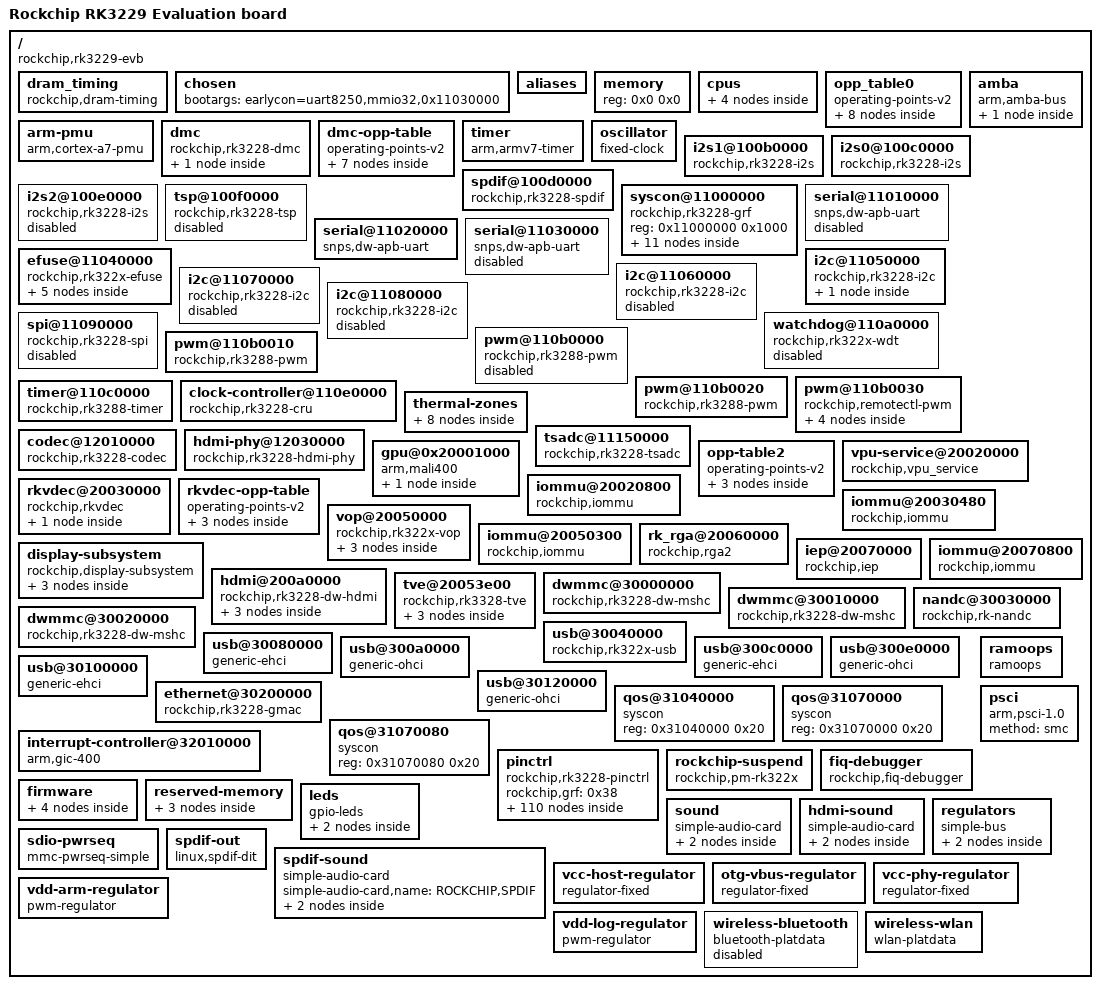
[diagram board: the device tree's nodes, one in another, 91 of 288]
/dts-v1/;

/ {
	#address-cells = <0x1>;
	#size-cells = <0x1>;
	interrupt-parent = <0x1>;
	model = "Rockchip RK3229 Evaluation board";
	compatible = "rockchip,rk3229-evb", "rockchip,rk3229";

	dram_timing {
		compatible = "rockchip,dram-timing";
		dram_spd_bin = <0x15>;
		sr_idle = <0x18>;
		pd_idle = <0x20>;
		dram_dll_disb_freq = <0x12c>;
		phy_dll_disb_freq = <0x190>;
		dram_odt_disb_freq = <0x190>;
		phy_odt_disb_freq = <0x190>;
		ddr3_drv = <0x0>;
		ddr3_odt = <0x40>;
		lpddr3_drv = <0x1>;
		lpddr3_odt = <0x3>;
		lpddr2_drv = <0x1>;
		phy_ddr3_clk_drv = <0x11>;
		phy_ddr3_cmd_drv = <0x11>;
		phy_ddr3_dqs_drv = <0x12>;
		phy_ddr3_odt = <0x2>;
		phy_lp23_clk_drv = <0x13>;
		phy_lp23_cmd_drv = <0x16>;
		phy_lp23_dqs_drv = <0x16>;
		phy_lp3_odt = <0x2>;
		phandle = <0xb>;
	};

	chosen {
		bootargs = "earlycon=uart8250,mmio32,0x11030000";
	};

	aliases {
		serial0 = "/serial@11010000";
		serial1 = "/serial@11020000";
		serial2 = "/serial@11030000";
		spi0 = "/spi@11090000";
	};

	memory {
		device_type = "memory";
		reg = <0x0 0x0>;
	};

	cpus {
		#address-cells = <0x1>;
		#size-cells = <0x0>;

		cpu@f00 {
			device_type = "cpu";
			compatible = "arm,cortex-a7";
			reg = <0xf00>;
			resets = <0x2 0x4>;
			operating-points-v2 = <0x3>;
			#cooling-cells = <0x2>;
			dynamic-power-coefficient = <0x7a>;
			clock-latency = <0x9c40>;
			clocks = <0x2 0x5>;
			enable-method = "psci";
			cpu-supply = <0x4>;
			phandle = <0x6>;
		};

		cpu@f01 {
			device_type = "cpu";
			compatible = "arm,cortex-a7";
			reg = <0xf01>;
			resets = <0x2 0x5>;
			operating-points-v2 = <0x3>;
			enable-method = "psci";
			phandle = <0x7>;
		};

		cpu@f02 {
			device_type = "cpu";
			compatible = "arm,cortex-a7";
			reg = <0xf02>;
			resets = <0x2 0x6>;
			operating-points-v2 = <0x3>;
			enable-method = "psci";
			phandle = <0x8>;
		};

		cpu@f03 {
			device_type = "cpu";
			compatible = "arm,cortex-a7";
			reg = <0xf03>;
			resets = <0x2 0x7>;
			operating-points-v2 = <0x3>;
			enable-method = "psci";
			phandle = <0x9>;
		};
	};

	opp_table0 {
		compatible = "operating-points-v2";
		opp-shared;
		clocks = <0x2 0x1>;
		rockchip,max-volt = <0x149970>;
		rockchip,leakage-voltage-sel = <0x1 0x4 0x0 0x5 0xfe 0x1>;
		nvmem-cells = <0x5>;
		nvmem-cell-names = "cpu_leakage";
		phandle = <0x3>;

		opp-408000000 {
			opp-hz = <0x0 0x18519600>;
			opp-microvolt = <0x12b128>;
			opp-microvolt-L0 = <0x12b128>;
			opp-microvolt-L1 = <0x12b128>;
			clock-latency-ns = <0x9c40>;
			opp-suspend;
		};

		opp-600000000 {
			opp-hz = <0x0 0x23c34600>;
			opp-microvolt = <0x1312d0>;
			opp-microvolt-L0 = <0x1312d0>;
			opp-microvolt-L1 = <0x1312d0>;
		};

		opp-816000000 {
			opp-hz = <0x0 0x30a32c00>;
			opp-microvolt = <0x137478>;
			opp-microvolt-L0 = <0x137478>;
			opp-microvolt-L1 = <0x137478>;
		};

		opp-1008000000 {
			opp-hz = <0x0 0x3c14dc00>;
			opp-microvolt = <0x13d620>;
			opp-microvolt-L0 = <0x13d620>;
			opp-microvolt-L1 = <0x13d620>;
		};

		opp-1200000000 {
			opp-hz = <0x0 0x47868c00>;
			opp-microvolt = <0x1437c8>;
			opp-microvolt-L0 = <0x1437c8>;
			opp-microvolt-L1 = <0x1437c8>;
		};

		opp-1296000000 {
			opp-hz = <0x0 0x4d3f6400>;
			opp-microvolt = <0x1437c8>;
			opp-microvolt-L0 = <0x1437c8>;
			opp-microvolt-L1 = <0x1437c8>;
		};

		opp-1392000000 {
			opp-hz = <0x0 0x52f83c00>;
			opp-microvolt = <0x149970>;
			opp-microvolt-L0 = <0x149970>;
			opp-microvolt-L1 = <0x149970>;
		};

		opp-1464000000 {
			opp-hz = <0x0 0x5742de00>;
			opp-microvolt = <0x149970>;
			opp-microvolt-L0 = <0x149970>;
			opp-microvolt-L1 = <0x149970>;
		};
	};

	amba {
		compatible = "arm,amba-bus";
		#address-cells = <0x1>;
		#size-cells = <0x1>;
		ranges;

		pdma@110f0000 {
			compatible = "arm,pl330", "arm,primecell";
			reg = <0x110f0000 0x4000>;
			interrupts = <0x0 0x0 0x4 0x0 0x1 0x4>;
			#dma-cells = <0x1>;
			clocks = <0x2 0xc2>;
			clock-names = "apb_pclk";
			peripherals-req-type-burst;
			phandle = <0xe>;
		};
	};

	arm-pmu {
		compatible = "arm,cortex-a7-pmu";
		interrupts = <0x0 0x4c 0x4 0x0 0x4d 0x4 0x0 0x4e 0x4 0x0 0x4f 0x4>;
		interrupt-affinity = <0x6 0x7 0x8 0x9>;
	};

	dmc {
		compatible = "rockchip,rk3228-dmc", "rockchip,rk322x-dram";
		clocks = <0x2 0x90>;
		clock-names = "dmc_clk";
		operating-points-v2 = <0xa>;
		system-status-freq = <0x1 0xc3500 0x10 0xc3500 0x10000 0xc3500>;
		dram_freq = <0x2faf0800>;
		rockchip,dram_timing = <0xb>;
		#cooling-cells = <0x2>;
		status = "okay";
		center-supply = <0xc>;

		ddr_power_model {
			compatible = "ddr_power_model";
			dynamic-power-coefficient = <0x78>;
			static-power-coefficient = <0xc8>;
			ts = <0x7d00 0x125c 0xffffffb0 0x2>;
			thermal-zone = "soc-thermal";
		};
	};

	dmc-opp-table {
		compatible = "operating-points-v2";
		rockchip,leakage-voltage-sel = <0x1 0x5 0x0 0x6 0xfe 0x1>;
		nvmem-cells = <0xd>;
		nvmem-cell-names = "ddr_leakage";
		phandle = <0xa>;

		opp-300000000 {
			opp-hz = <0x0 0x11e1a300>;
			opp-microvolt = <0x100590>;
			opp-microvolt-L0 = <0x100590>;
			opp-microvolt-L1 = <0xf4240>;
		};

		opp-400000000 {
			opp-hz = <0x0 0x17d78400>;
			opp-microvolt = <0x100590>;
			opp-microvolt-L0 = <0x100590>;
			opp-microvolt-L1 = <0xf4240>;
		};

		opp-600000000 {
			opp-hz = <0x0 0x23c34600>;
			opp-microvolt = <0x10c8e0>;
			opp-microvolt-L0 = <0x10c8e0>;
			opp-microvolt-L1 = <0x100590>;
		};

		opp-666000000 {
			opp-hz = <0x0 0x27b25a80>;
			opp-microvolt = <0x118c30>;
			opp-microvolt-L0 = <0x118c30>;
			opp-microvolt-L1 = <0x10c8e0>;
		};

		opp-700000000 {
			opp-hz = <0x0 0x29b92700>;
			opp-microvolt = <0x118c30>;
			opp-microvolt-L0 = <0x118c30>;
			opp-microvolt-L1 = <0x10c8e0>;
		};

		opp-786000000 {
			opp-hz = <0x0 0x2ed96880>;
			opp-microvolt = <0x118c30>;
			opp-microvolt-L0 = <0x118c30>;
			opp-microvolt-L1 = <0x10c8e0>;
		};

		opp-800000000 {
			opp-hz = <0x0 0x2faf0800>;
			opp-microvolt = <0x118c30>;
			opp-microvolt-L0 = <0x118c30>;
			opp-microvolt-L1 = <0x10c8e0>;
		};
	};

	timer {
		compatible = "arm,armv7-timer";
		interrupts = <0x1 0xd 0xf04 0x1 0xe 0xf04 0x1 0xb 0xf04 0x1 0xa 0xf04>;
		clock-frequency = <0x16e3600>;
	};

	oscillator {
		compatible = "fixed-clock";
		clock-frequency = <0x16e3600>;
		clock-output-names = "xin24m";
		#clock-cells = <0x0>;
		phandle = <0x37>;
	};

	i2s1@100b0000 {
		compatible = "rockchip,rk3228-i2s", "rockchip,rk3066-i2s";
		reg = <0x100b0000 0x4000>;
		interrupts = <0x0 0x1b 0x4>;
		#address-cells = <0x1>;
		#size-cells = <0x0>;
		clock-names = "i2s_clk", "i2s_hclk";
		clocks = <0x2 0x51 0x2 0x1bb>;
		dmas = <0xe 0xe 0xe 0xf>;
		dma-names = "tx", "rx";
		pinctrl-names = "default";
		pinctrl-0 = <0xf>;
		status = "okay";
		#sound-dai-cells = <0x0>;
		phandle = <0x68>;
	};

	i2s0@100c0000 {
		compatible = "rockchip,rk3228-i2s", "rockchip,rk3066-i2s";
		reg = <0x100c0000 0x4000>;
		interrupts = <0x0 0x1a 0x4>;
		#address-cells = <0x1>;
		#size-cells = <0x0>;
		clock-names = "i2s_clk", "i2s_hclk";
		clocks = <0x2 0x50 0x2 0x1ba>;
		dmas = <0xe 0xb 0xe 0xc>;
		dma-names = "tx", "rx";
		status = "okay";
		rockchip,bclk-fs = <0x80>;
		#sound-dai-cells = <0x0>;
		phandle = <0x6a>;
	};

	spdif@100d0000 {
		compatible = "rockchip,rk3228-spdif";
		reg = <0x100d0000 0x1000>;
		interrupts = <0x0 0x1d 0x4>;
		clocks = <0x2 0x53 0x2 0x1bd>;
		clock-names = "mclk", "hclk";
		dmas = <0xe 0xa>;
		#dma-cells = <0x1>;
		dma-names = "tx";
		pinctrl-names = "default";
		pinctrl-0 = <0x10>;
		status = "okay";
		#sound-dai-cells = <0x0>;
		phandle = <0x6e>;
	};

	i2s2@100e0000 {
		compatible = "rockchip,rk3228-i2s", "rockchip,rk3066-i2s";
		reg = <0x100e0000 0x4000>;
		interrupts = <0x0 0x1c 0x4>;
		#address-cells = <0x1>;
		#size-cells = <0x0>;
		clock-names = "i2s_clk", "i2s_hclk";
		clocks = <0x2 0x52 0x2 0x1bc>;
		dmas = <0xe 0x0 0xe 0x1>;
		dma-names = "tx", "rx";
		status = "disabled";
	};

	tsp@100f0000 {
		compatible = "rockchip,rk3228-tsp";
		reg = <0x100f0000 0x10000>;
		interrupts = <0x0 0x48 0x4>;
		interrupt-names = "irq_tsp";
		clocks = <0x2 0x8b 0x2 0x1db 0x2 0x8c>;
		clock-names = "clk_tsp", "hclk_tsp", "aclk_tsp";
		pinctrl-names = "default";
		pinctrl-0 = <0x11 0x12 0x13 0x14 0x15 0x16 0x17 0x18 0x19 0x1a 0x1b 0x1c>;
		status = "disabled";
	};

	syscon@11000000 {
		compatible = "rockchip,rk3228-grf", "syscon", "simple-mfd";
		reg = <0x11000000 0x1000>;
		#address-cells = <0x1>;
		#size-cells = <0x1>;
		phandle = <0x38>;

		io-domains {
			compatible = "rockchip,rk322x-io-voltage-domain";
			status = "okay";
			vccio1-supply = <0x1d>;
			vccio2-supply = <0x1e>;
			vccio4-supply = <0x1d>;
		};

		reboot-mode {
			compatible = "syscon-reboot-mode";
			offset = <0x5c8>;
			mode-normal = <0x5242c300>;
			mode-recovery = <0x5242c303>;
			mode-bootloader = <0x5242c309>;
			mode-loader = <0x5242c301>;
			mode-ums = <0x5242c30c>;
		};

		usb2-phy@760 {
			compatible = "rockchip,rk322x-usb2phy";
			reg = <0x760 0xc>;
			clocks = <0x2 0x8e>;
			clock-names = "phyclk";
			#clock-cells = <0x0>;
			clock-output-names = "usb480m_phy0";
			status = "okay";
			phandle = <0x5c>;

			otg-port {
				#phy-cells = <0x0>;
				interrupts = <0x0 0x3b 0x4 0x0 0x3c 0x4 0x0 0x3d 0x4>;
				interrupt-names = "otg-bvalid", "otg-id", "linestate";
				status = "okay";
				vbus-supply = <0x1f>;
				phandle = <0x5b>;
			};

			host-port {
				#phy-cells = <0x0>;
				interrupts = <0x0 0x3e 0x4>;
				interrupt-names = "linestate";
				status = "okay";
				phy-supply = <0x20>;
				phandle = <0x5d>;
			};
		};

		usb2-phy@800 {
			compatible = "rockchip,rk322x-usb2phy";
			reg = <0x800 0xc>;
			clocks = <0x2 0x8f>;
			clock-names = "phyclk";
			#clock-cells = <0x0>;
			clock-output-names = "usb480m_phy1";
			status = "okay";
			phandle = <0x5e>;

			otg-port {
				#phy-cells = <0x0>;
				interrupts = <0x0 0x45 0x4>;
				interrupt-names = "linestate";
				status = "okay";
				phandle = <0x60>;
			};

			host-port {
				#phy-cells = <0x0>;
				interrupts = <0x0 0x44 0x4>;
				interrupt-names = "linestate";
				status = "okay";
				phy-supply = <0x20>;
				phandle = <0x5f>;
			};
		};

		power-controller {
			compatible = "rockchip,rk3228-power-controller";
			#power-domain-cells = <0x1>;
			#address-cells = <0x1>;
			#size-cells = <0x0>;
			status = "okay";
			phandle = <0x41>;

			pd_vpu@6 {
				reg = <0x6>;
				clocks = <0x2 0xca 0x2 0x1d0>;
				pm_qos = <0x21>;
			};

			pd_rkvdec@7 {
				reg = <0x7>;
				clocks = <0x2 0xcb 0x2 0x1d1 0x2 0x85 0x2 0x86>;
				pm_qos = <0x22 0x23>;
			};
		};
	};

	serial@11010000 {
		compatible = "snps,dw-apb-uart";
		reg = <0x11010000 0x100>;
		interrupts = <0x0 0x37 0x4>;
		clock-frequency = <0x16e3600>;
		clocks = <0x2 0x4d 0x2 0x155>;
		clock-names = "baudclk", "apb_pclk";
		pinctrl-names = "default";
		pinctrl-0 = <0x24 0x25 0x26>;
		reg-shift = <0x2>;
		reg-io-width = <0x4>;
		status = "disabled";
	};

	serial@11020000 {
		compatible = "snps,dw-apb-uart";
		reg = <0x11020000 0x100>;
		interrupts = <0x0 0x38 0x4>;
		clock-frequency = <0x16e3600>;
		clocks = <0x2 0x4e 0x2 0x156>;
		clock-names = "baudclk", "apb_pclk";
		pinctrl-names = "default";
		pinctrl-0 = <0x27 0x28>;
		reg-shift = <0x2>;
		reg-io-width = <0x4>;
		status = "okay";
	};

	serial@11030000 {
		compatible = "snps,dw-apb-uart";
		reg = <0x11030000 0x100>;
		interrupts = <0x0 0x39 0x4>;
		clock-frequency = <0x16e3600>;
		clocks = <0x2 0x4f 0x2 0x157>;
		clock-names = "baudclk", "apb_pclk";
		pinctrl-names = "default";
		pinctrl-0 = <0x29>;
		reg-shift = <0x2>;
		reg-io-width = <0x4>;
		status = "disabled";
	};

	efuse@11040000 {
		compatible = "rockchip,rk322x-efuse";
		reg = <0x11040000 0x20>;
		#address-cells = <0x1>;
		#size-cells = <0x1>;
		clocks = <0x2 0x147>;
		clock-names = "pclk_efuse";

		id@7 {
			reg = <0x7 0x10>;
		};

		cpu_leakage@17 {
			reg = <0x17 0x1>;
			phandle = <0x5>;
		};

		logic-leakage@19 {
			reg = <0x19 0x1>;
			phandle = <0xd>;
		};

		hdmi_phy_flag@1d {
			reg = <0x1d 0x1>;
			bits = <0x1 0x1>;
			phandle = <0x3f>;
		};

		tve_dac@1d {
			reg = <0x1d 0x1>;
			bits = <0x3 0x5>;
			phandle = <0x52>;
		};
	};

	i2c@11050000 {
		compatible = "rockchip,rk3228-i2c";
		reg = <0x11050000 0x1000>;
		interrupts = <0x0 0x24 0x4>;
		#address-cells = <0x1>;
		#size-cells = <0x0>;
		clock-names = "i2c";
		clocks = <0x2 0x14c>;
		pinctrl-names = "default";
		pinctrl-0 = <0x2a>;
		status = "okay";

		hym8563@51 {
			compatible = "haoyu,hym8563";
			reg = <0x51>;
			#clock-cells = <0x0>;
			clock-frequency = <0x8000>;
			clock-output-names = "xin32k";
			phandle = <0x74>;
		};
	};

	i2c@11060000 {
		compatible = "rockchip,rk3228-i2c";
		reg = <0x11060000 0x1000>;
		interrupts = <0x0 0x25 0x4>;
		#address-cells = <0x1>;
		#size-cells = <0x0>;
		clock-names = "i2c";
		clocks = <0x2 0x14d>;
		pinctrl-names = "default";
		pinctrl-0 = <0x2b>;
		status = "disabled";
	};

	i2c@11070000 {
		compatible = "rockchip,rk3228-i2c";
		reg = <0x11070000 0x1000>;
		interrupts = <0x0 0x26 0x4>;
		#address-cells = <0x1>;
		#size-cells = <0x0>;
		clock-names = "i2c";
		clocks = <0x2 0x14e>;
		pinctrl-names = "default";
		pinctrl-0 = <0x2c>;
		status = "disabled";
	};

	i2c@11080000 {
		compatible = "rockchip,rk3228-i2c";
		reg = <0x11080000 0x1000>;
		interrupts = <0x0 0x27 0x4>;
		#address-cells = <0x1>;
		#size-cells = <0x0>;
		clock-names = "i2c";
		clocks = <0x2 0x14f>;
		pinctrl-names = "default";
		pinctrl-0 = <0x2d>;
		status = "disabled";
	};

	spi@11090000 {
		compatible = "rockchip,rk3228-spi";
		reg = <0x11090000 0x1000>;
		interrupts = <0x0 0x31 0x4>;
		#address-cells = <0x1>;
		#size-cells = <0x0>;
		pinctrl-names = "default";
		pinctrl-0 = <0x2e 0x2f 0x30 0x31 0x32>;
		clocks = <0x2 0x41 0x2 0x152>;
		clock-names = "spiclk", "apb_pclk";
		status = "disabled";
	};

	watchdog@110a0000 {
		compatible = "rockchip,rk322x-wdt", "snps,dw-wdt";
		reg = <0x110a0000 0x100>;
		clocks = <0x2 0x162>;
		interrupts = <0x0 0x28 0x4>;
		status = "disabled";
	};

	pwm@110b0000 {
		compatible = "rockchip,rk3288-pwm";
		reg = <0x110b0000 0x10>;
		#pwm-cells = <0x3>;
		clocks = <0x2 0x15e>;
		clock-names = "pwm";
		pinctrl-names = "active";
		pinctrl-0 = <0x33>;
		status = "disabled";
	};

	pwm@110b0010 {
		compatible = "rockchip,rk3288-pwm";
		reg = <0x110b0010 0x10>;
		#pwm-cells = <0x3>;
		clocks = <0x2 0x15e>;
		clock-names = "pwm";
		pinctrl-names = "active";
		pinctrl-0 = <0x34>;
		status = "okay";
		phandle = <0x72>;
	};

	pwm@110b0020 {
		compatible = "rockchip,rk3288-pwm";
		reg = <0x110b0020 0x10>;
		#pwm-cells = <0x3>;
		clocks = <0x2 0x15e>;
		clock-names = "pwm";
		pinctrl-names = "active";
		pinctrl-0 = <0x35>;
		status = "okay";
		phandle = <0x73>;
	};

	pwm@110b0030 {
		compatible = "rockchip,remotectl-pwm";
		reg = <0x110b0030 0x10>;
		interrupts = <0x0 0x32 0x4>;
		#pwm-cells = <0x3>;
		clocks = <0x2 0x15e>;
		clock-names = "pwm";
		pinctrl-names = "active";
		pinctrl-0 = <0x36>;
		status = "okay";
		remote_pwm_id = <0x3>;
		handle_cpu_id = <0x1>;
		remote_support_psci = <0x1>;

		ir_key1 {
			rockchip,usercode = <0x4040>;
			rockchip,key_table = <0xf2 0xe8 0xba 0x9e 0xf4 0x67 0xf1 0x6c 0xef 0x69 0xee 0x6a 0xbd 0x66 0xea 0x73 0xe3 0x72 0xe2 0xd9 0xb2 0x74 0xbc 0x71 0xec 0x8b 0xbf 0x190 0xe0 0x191 0xe1 0x192 0xe9 0xb7 0xe6 0xf8 0xe8 0xb9 0xe7 0xba 0xf0 0x184 0xbe 0x175>;
		};

		ir_key2 {
			rockchip,usercode = <0xff00>;
			rockchip,key_table = <0xf9 0x66 0xbf 0x9e 0xfb 0x8b 0xaa 0xe8 0xb9 0x67 0xe9 0x6c 0xb8 0x69 0xea 0x6a 0xeb 0x72 0xef 0x73 0xf7 0x71 0xe7 0x74 0xfc 0x74 0xa9 0x72 0xa8 0xa4 0xe0 0x72 0xa5 0x72 0xab 0xb7 0xb7 0x184 0xe8 0x184 0xf8 0xb8 0xaf 0xb9 0xed 0x72 0xee 0xba 0xb3 0x72 0xf1 0x72 0xf2 0x72 0xf3 0xd9 0xb4 0x72 0xa4 0x8d 0xbe 0xd9>;
		};

		ir_key3 {
			rockchip,usercode = <0x1dcc>;
			rockchip,key_table = <0xee 0xe8 0xf0 0x9e 0xf8 0x67 0xbb 0x6c 0xef 0x69 0xed 0x6a 0xfc 0x66 0xf1 0x73 0xfd 0x72 0xb7 0xd9 0xff 0x74 0xf3 0x71 0xbf 0x8b 0xf9 0x191 0xf5 0x192 0xb3 0x184 0xbe 0x2 0xba 0x3 0xb2 0x4 0xbd 0x5 0xf9 0x6 0xb1 0x7 0xfc 0x8 0xf8 0x9 0xb0 0xa 0xb6 0xb 0xb5 0xe>;
		};

		ir_key4 {
			rockchip,usercode = <0xfe01>;
			rockchip,key_table = <0xec 0xe8 0xe6 0x9e 0xe9 0x67 0xe5 0x6c 0xae 0x69 0xaf 0x6a 0xee 0x66 0xe7 0x73 0xef 0x72 0xbf 0x74 0xbe 0x71 0xb3 0x8b 0xff 0x184 0xb1 0x2 0xf2 0x3 0xf3 0x4 0xb5 0x5 0xf6 0x6 0xf7 0x7 0xb9 0x8 0xfa 0x9 0xfb 0xa 0xfe 0xb 0xbd 0xe 0xbc 0xb7 0xf0 0xba 0xb4 0x19c 0xb0 0x197>;
		};
	};

	timer@110c0000 {
		compatible = "rockchip,rk3288-timer";
		reg = <0x110c0000 0x20>;
		interrupts = <0x0 0x2b 0x4>;
		clocks = <0x37 0x2 0x161>;
		clock-names = "timer", "pclk";
	};

	clock-controller@110e0000 {
		compatible = "rockchip,rk3228-cru";
		reg = <0x110e0000 0x1000>;
		rockchip,grf = <0x38>;
		#clock-cells = <0x1>;
		#reset-cells = <0x1>;
		assigned-clocks = <0x2 0x4 0x2 0x5 0x2 0x3 0x2 0xd2 0x2 0x1de 0x2 0x16b 0x2 0xc3 0x2 0x1cc 0x2 0x162 0x2 0xd3>;
		assigned-clock-rates = <0x47868c00 0x30a32c00 0x1dcd6500 0x8f0d180 0x8f0d180 0x47868c0 0x8f0d180 0x8f0d180 0x47868c0 0x17d78400>;
		phandle = <0x2>;
	};

	thermal-zones {

		soc-thermal {
			polling-delay-passive = <0x64>;
			polling-delay = <0x1388>;
			sustainable-power = <0x4b0>;
			thermal-sensors = <0x39 0x0>;

			trips {

				trip-point@0 {
					temperature = <0x15f90>;
					hysteresis = <0x7d0>;
					type = "passive";
				};

				trip-point@1 {
					temperature = <0x19a28>;
					hysteresis = <0x7d0>;
					type = "passive";
					phandle = <0x3a>;
				};

				soc-crit {
					temperature = <0x1adb0>;
					hysteresis = <0x7d0>;
					type = "critical";
				};
			};

			cooling-maps {

				map0 {
					trip = <0x3a>;
					cooling-device = <0x6 0xffffffff 0xffffffff>;
					contribution = <0x400>;
				};

				map1 {
					trip = <0x3a>;
					cooling-device = <0x3b 0xffffffff 0xffffffff>;
					contribution = <0x400>;
				};
			};
		};
	};

	tsadc@11150000 {
		compatible = "rockchip,rk3228-tsadc";
		reg = <0x11150000 0x100>;
		interrupts = <0x0 0x3a 0x4>;
		clocks = <0x2 0x48 0x2 0x158>;
		clock-names = "tsadc", "apb_pclk";
		assigned-clocks = <0x2 0x48>;
		assigned-clock-rates = <0x8000>;
		resets = <0x2 0x57>;
		reset-names = "tsadc-apb";
		pinctrl-names = "init", "default", "sleep";
		pinctrl-0 = <0x3c>;
		pinctrl-1 = <0x3d>;
		pinctrl-2 = <0x3c>;
		#thermal-sensor-cells = <0x0>;
		rockchip,hw-tshut-temp = <0x1d4c0>;
		status = "okay";
		rockchip,hw-tshut-mode = <0x0>;
		phandle = <0x39>;
	};

	codec@12010000 {
		compatible = "rockchip,rk3228-codec";
		reg = <0x12010000 0x1000>;
		clocks = <0x2 0x71 0x2 0x170 0x2 0x51>;
		clock-names = "mclk", "pclk", "sclk";
		spk-en-gpio = <0x3e 0x3 0x0>;
		status = "okay";
		#sound-dai-cells = <0x0>;
		phandle = <0x69>;
	};

	hdmi-phy@12030000 {
		compatible = "rockchip,rk3228-hdmi-phy";
		reg = <0x12030000 0x10000>;
		#phy-cells = <0x0>;
		clocks = <0x2 0x16d 0x37>;
		clock-names = "sysclk", "refclk";
		#clock-cells = <0x0>;
		clock-output-names = "hdmiphy_phy";
		nvmem-cells = <0x3f>;
		nvmem-cell-names = "hdmi_phy_flag";
		status = "okay";
		phandle = <0x51>;
	};

	gpu@0x20001000 {
		compatible = "arm,mali400";
		reg = <0x20001000 0x200 0x20000000 0x100 0x20003000 0x100 0x20008000 0x1100 0x20004000 0x100 0x2000a000 0x1100 0x20005000 0x100>;
		reg-names = "Mali_L2", "Mali_GP", "Mali_GP_MMU", "Mali_PP0", "Mali_PP0_MMU", "Mali_PP1", "Mali_PP1_MMU";
		interrupts = <0x0 0x6 0x4 0x0 0x5 0x4 0x0 0x4 0x4 0x0 0x5 0x4 0x0 0x4 0x4 0x0 0x5 0x4>;
		interrupt-names = "Mali_GP_IRQ", "Mali_GP_MMU_IRQ", "Mali_PP0_IRQ", "Mali_PP0_MMU_IRQ", "Mali_PP1_IRQ", "Mali_PP1_MMU_IRQ";
		clocks = <0x2 0xd5>;
		#cooling-cells = <0x2>;
		clock-names = "clk_mali";
		operating-points-v2 = <0x40>;
		status = "okay";
		mali-supply = <0xc>;
		phandle = <0x3b>;

		power_model {
			compatible = "arm,mali-simple-power-model";
			voltage = <0x384>;
			frequency = <0x1f4>;
			static-power = <0x12c>;
			dynamic-power = <0x18c>;
			ts = <0x7d00 0x125c 0xffffffb0 0x2>;
			thermal-zone = "soc-thermal";
		};
	};

	opp-table2 {
		compatible = "operating-points-v2";
		rockchip,leakage-voltage-sel = <0x1 0x5 0x0 0x6 0xfe 0x1>;
		nvmem-cells = <0xd>;
		nvmem-cell-names = "gpu_leakage";
		phandle = <0x40>;

		opp-200000000 {
			opp-hz = <0x0 0xbebc200>;
			opp-microvolt = <0x100590>;
			opp-microvolt-L0 = <0x100590>;
			opp-microvolt-L1 = <0x100590>;
		};

		opp-300000000 {
			opp-hz = <0x0 0x11e1a300>;
			opp-microvolt = <0x10c8e0>;
			opp-microvolt-L0 = <0x10c8e0>;
			opp-microvolt-L1 = <0x10c8e0>;
		};

		opp-500000000 {
			opp-hz = <0x0 0x1dcd6500>;
			opp-microvolt = <0x118c30>;
			opp-microvolt-L0 = <0x118c30>;
			opp-microvolt-L1 = <0x118c30>;
		};
	};

	vpu-service@20020000 {
		compatible = "rockchip,vpu_service";
		reg = <0x20020000 0x800>;
		interrupts = <0x0 0x9 0x4 0x0 0xb 0x4>;
		interrupt-names = "irq_dec", "irq_enc";
		resets = <0x2 0x70 0x2 0x71>;
		reset-names = "video_a", "video_h";
		clocks = <0x2 0xca 0x2 0x1d0>;
		clock-names = "aclk_vcodec", "hclk_vcodec";
		power-domains = <0x41 0x6>;
		rockchip,grf = <0x38>;
		iommus = <0x42>;
		allocator = <0x1>;
		status = "okay";
	};

	iommu@20020800 {
		compatible = "rockchip,iommu";
		reg = <0x20020800 0x40>;
		interrupts = <0x0 0xa 0x4>;
		interrupt-names = "vpu_mmu";
		clock-names = "aclk", "hclk";
		clocks = <0x2 0xca 0x2 0x1d0>;
		power-domains = <0x41 0x6>;
		#iommu-cells = <0x0>;
		status = "okay";
		phandle = <0x42>;
	};

	rkvdec@20030000 {
		compatible = "rockchip,rkvdec";
		reg = <0x20030000 0x400>;
		interrupts = <0x0 0x7 0x4>;
		interrupt-names = "irq_dec";
		clocks = <0x2 0xcb 0x2 0x1d1 0x2 0x85 0x2 0x86>;
		clock-names = "aclk_vcodec", "hclk_vcodec", "clk_cabac", "clk_core";
		resets = <0x2 0x76 0x2 0x78 0x2 0x77 0x2 0x79 0x2 0x7b 0x2 0x7a>;
		reset-names = "video_a", "video_h", "niu_a", "niu_h", "video_cabac", "video_core";
		power-domains = <0x41 0x7>;
		operating-points-v2 = <0x43>;
		#cooling-cells = <0x2>;
		rockchip,grf = <0x38>;
		iommus = <0x44>;
		allocator = <0x1>;
		status = "okay";
		vcodec-supply = <0xc>;

		vcodec_power_model {
			compatible = "vcodec_power_model";
			dynamic-power-coefficient = <0x78>;
			static-power-coefficient = <0xc8>;
			ts = <0x7d00 0x125c 0xffffffb0 0x2>;
			thermal-zone = "soc-thermal";
		};
	};

	rkvdec-opp-table {
		compatible = "operating-points-v2";
		rockchip,leakage-voltage-sel = <0x1 0x5 0x0 0x6 0xfe 0x1>;
		nvmem-cells = <0xd>;
		nvmem-cell-names = "rkvdec_leakage";
		phandle = <0x43>;

		opp-100000000 {
			opp-hz = <0x0 0x5f5e100>;
			opp-microvolt = <0x100590>;
			opp-microvolt-L0 = <0x100590>;
			opp-microvolt-L1 = <0xf4240>;
		};

		opp-200000000 {
			opp-hz = <0x0 0xbebc200>;
			opp-microvolt = <0x100590>;
			opp-microvolt-L0 = <0x100590>;
			opp-microvolt-L1 = <0xf4240>;
		};

		opp-500000000 {
			opp-hz = <0x0 0x1dcd6500>;
			opp-microvolt = <0x100590>;
			opp-microvolt-L0 = <0x100590>;
			opp-microvolt-L1 = <0xf4240>;
		};
	};

	iommu@20030480 {
		compatible = "rockchip,iommu";
		reg = <0x20030480 0x40 0x200304c0 0x40>;
		interrupts = <0x0 0x8 0x4>;
		interrupt-names = "rkvdec_mmu";
		clocks = <0x2 0xcb 0x2 0x1d1>;
		clock-names = "aclk", "hclk";
		power-domains = <0x41 0x7>;
		#iommu-cells = <0x0>;
		status = "okay";
		phandle = <0x44>;
	};

	vop@20050000 {
		compatible = "rockchip,rk322x-vop";
		reg = <0x20050000 0x1ffc>;
		reg-names = "regs";
		interrupts = <0x0 0x20 0x4>;
		clocks = <0x2 0xd3 0x2 0xbe 0x2 0x1c4>;
		clock-names = "aclk_vop", "dclk_vop", "hclk_vop";
		resets = <0x2 0x64 0x2 0x65 0x2 0x66>;
		reset-names = "axi", "ahb", "dclk";
		iommus = <0x45>;
		status = "okay";
		assigned-clocks = <0x2 0xbe>;
		assigned-clock-parents = <0x2 0xc0>;

		port {
			#address-cells = <0x1>;
			#size-cells = <0x0>;
			phandle = <0x49>;

			endpoint@0 {
				reg = <0x0>;
				remote-endpoint = <0x46>;
				phandle = <0x4c>;
			};

			endpoint@1 {
				reg = <0x1>;
				remote-endpoint = <0x47>;
				phandle = <0x4d>;
			};
		};
	};

	iommu@20050300 {
		compatible = "rockchip,iommu";
		reg = <0x20053f00 0x100>;
		interrupts = <0x0 0x20 0x4>;
		interrupt-names = "vop_mmu";
		clocks = <0x2 0xd3 0x2 0x1c4>;
		clock-names = "aclk", "hclk";
		#iommu-cells = <0x0>;
		status = "okay";
		phandle = <0x45>;
	};

	rk_rga@20060000 {
		compatible = "rockchip,rga2";
		reg = <0x20060000 0x1000>;
		interrupts = <0x0 0x21 0x4>;
		clocks = <0x2 0xcd 0x2 0x1d3 0x2 0x87>;
		clock-names = "aclk_rga", "hclk_rga", "clk_rga";
		dma-coherent;
		status = "okay";
	};

	iep@20070000 {
		compatible = "rockchip,iep";
		iommu_enabled = <0x1>;
		iommus = <0x48>;
		reg = <0x20070000 0x800>;
		interrupts = <0x0 0x1f 0x4>;
		clocks = <0x2 0xcc 0x2 0x1d4>;
		clock-names = "aclk_iep", "hclk_iep";
		version = <0x3>;
		allocator = <0x1>;
		status = "okay";
	};

	iommu@20070800 {
		compatible = "rockchip,iommu";
		reg = <0x20070800 0x40>;
		interrupts = <0x0 0x1f 0x4>;
		interrupt-names = "iep_mmu";
		#iommu-cells = <0x0>;
		status = "okay";
		phandle = <0x48>;
	};

	display-subsystem {
		compatible = "rockchip,display-subsystem";
		ports = <0x49>;
		logo-memory-region = <0x4a>;
		status = "okay";
		secure-memory-region = <0x4b>;

		route {

			route-hdmi {
				status = "okay";
				logo,uboot = "logo.bmp";
				logo,kernel = "logo_kernel.bmp";
				logo,mode = "center";
				charge_logo,mode = "center";
				connect = <0x4c>;
			};

			route-tve {
				status = "okay";
				logo,uboot = "logo.bmp";
				logo,kernel = "logo_kernel.bmp";
				logo,mode = "center";
				charge_logo,mode = "center";
				connect = <0x4d>;
			};
		};
	};

	hdmi@200a0000 {
		compatible = "rockchip,rk3228-dw-hdmi";
		reg = <0x200a0000 0x20000>;
		reg-io-width = <0x4>;
		interrupts = <0x0 0x23 0x4 0x0 0x47 0x4>;
		clocks = <0x2 0x7b 0x2 0x16c 0x2 0x89>;
		clock-names = "isfr", "iahb", "cec";
		pinctrl-names = "default";
		pinctrl-0 = <0x4e 0x4f 0x50>;
		resets = <0x2 0x60>;
		reset-names = "hdmi";
		phys = <0x51>;
		phy-names = "hdmi_phy";
		rockchip,grf = <0x38>;
		status = "okay";
		#sound-dai-cells = <0x0>;
		ddc-i2c-scl-high-time-ns = <0x2599>;
		ddc-i2c-scl-low-time-ns = <0x2710>;
		phandle = <0x6b>;

		ports {

			port {
				#address-cells = <0x1>;
				#size-cells = <0x0>;

				endpoint@0 {
					reg = <0x0>;
					remote-endpoint = <0x4c>;
					phandle = <0x46>;
				};
			};
		};
	};

	tve@20053e00 {
		compatible = "rockchip,rk3328-tve";
		reg = <0x20053e00 0x100 0x12020000 0x10000>;
		rockchip,saturation = <0x305b46>;
		rockchip,brightcontrast = <0x9900>;
		rockchip,adjtiming = <0xd6c00880>;
		rockchip,lumafilter0 = <0x2ff0001>;
		rockchip,lumafilter1 = <0xf40200fe>;
		rockchip,lumafilter2 = <0xf332d910>;
		rockchip,daclevel = <0x15>;
		rockchip,dac1level = <0x7>;
		nvmem-cells = <0x52>;
		nvmem-cell-names = "tve_dac_adj";
		status = "okay";

		ports {

			port {
				#address-cells = <0x1>;
				#size-cells = <0x0>;

				endpoint@0 {
					reg = <0x0>;
					remote-endpoint = <0x4d>;
					phandle = <0x47>;
				};
			};
		};
	};

	dwmmc@30000000 {
		compatible = "rockchip,rk3228-dw-mshc", "rockchip,rk3288-dw-mshc";
		reg = <0x30000000 0x4000>;
		interrupts = <0x0 0xc 0x4>;
		clocks = <0x2 0x1c8 0x2 0x44 0x2 0x72 0x2 0x76>;
		clock-names = "biu", "ciu", "ciu-drive", "ciu-sample";
		fifo-depth = <0x100>;
		pinctrl-names = "default";
		pinctrl-0 = <0x53 0x54 0x55 0x56>;
		status = "okay";
		bus-width = <0x4>;
		cap-mmc-highspeed;
		cap-sd-highspeed;
		card-detect-delay = <0xc8>;
		disable-wp;
		max-frequency = <0x2faf080>;
		num-slots = <0x1>;
		supports-sd;
	};

	dwmmc@30010000 {
		compatible = "rockchip,rk3228-dw-mshc", "rockchip,rk3288-dw-mshc";
		reg = <0x30010000 0x4000>;
		interrupts = <0x0 0xd 0x4>;
		clocks = <0x2 0x1c9 0x2 0x45 0x2 0x73 0x2 0x77>;
		clock-names = "biu", "ciu", "ciu-drive", "ciu-sample";
		fifo-depth = <0x100>;
		pinctrl-names = "default";
		pinctrl-0 = <0x57 0x58 0x59>;
		status = "okay";
		bus-width = <0x4>;
		cap-mmc-highspeed;
		cap-sd-highspeed;
		cap-sdio-irq;
		non-removable;
		ignore-pm-notify;
		keep-power-in-suspend;
		max-frequency = <0x23c3460>;
		supports-sdio;
		mmc-pwrseq = <0x5a>;
	};

	dwmmc@30020000 {
		compatible = "rockchip,rk3228-dw-mshc", "rockchip,rk3288-dw-mshc";
		reg = <0x30020000 0x4000>;
		interrupts = <0x0 0xe 0x4>;
		clock-frequency = <0x23c3460>;
		clock-freq-min-max = <0x61a80 0x23c3460>;
		clocks = <0x2 0x1cb 0x2 0x47 0x2 0x75 0x2 0x79>;
		clock-names = "biu", "ciu", "ciu-drive", "ciu-sample";
		bus-width = <0x8>;
		num-slots = <0x1>;
		fifo-depth = <0x100>;
		status = "okay";
		broken-cd;
		cap-mmc-highspeed;
		supports-emmc;
		disable-wp;
		non-removable;
	};

	nandc@30030000 {
		compatible = "rockchip,rk-nandc";
		reg = <0x30030000 0x4000>;
		interrupts = <0x0 0xf 0x4>;
		nandc_id = <0x0>;
		clocks = <0x2 0x43 0x2 0x1c5>;
		clock-names = "clk_nandc", "hclk_nandc";
		status = "okay";
	};

	usb@30040000 {
		compatible = "rockchip,rk322x-usb", "rockchip,rk3066-usb", "snps,dwc2";
		reg = <0x30040000 0x40000>;
		interrupts = <0x0 0x17 0x4>;
		clocks = <0x2 0x1da>;
		clock-names = "otg";
		dr_mode = "host";
		g-np-tx-fifo-size = <0x10>;
		g-rx-fifo-size = <0x118>;
		g-tx-fifo-size = <0x100 0x80 0x80 0x40 0x20 0x10>;
		g-use-dma;
		phys = <0x5b>;
		phy-names = "usb2-phy";
		status = "okay";
	};

	usb@30080000 {
		compatible = "generic-ehci";
		reg = <0x30080000 0x20000>;
		interrupts = <0x0 0x10 0x4>;
		clocks = <0x2 0x1d7 0x5c>;
		clock-names = "usbhost", "utmi";
		phys = <0x5d>;
		phy-names = "usb";
		status = "okay";
	};

	usb@300a0000 {
		compatible = "generic-ohci";
		reg = <0x300a0000 0x20000>;
		interrupts = <0x0 0x11 0x4>;
		clocks = <0x2 0x1d7 0x5c>;
		clock-names = "usbhost", "utmi";
		phys = <0x5d>;
		phy-names = "usb";
		status = "okay";
	};

	usb@300c0000 {
		compatible = "generic-ehci";
		reg = <0x300c0000 0x20000>;
		interrupts = <0x0 0x13 0x4>;
		clocks = <0x2 0x1d8 0x5e>;
		clock-names = "usbhost", "utmi";
		phys = <0x5f>;
		phy-names = "usb";
		status = "okay";
	};

	usb@300e0000 {
		compatible = "generic-ohci";
		reg = <0x300e0000 0x20000>;
		interrupts = <0x0 0x14 0x4>;
		clocks = <0x2 0x1d8 0x5e>;
		clock-names = "usbhost", "utmi";
		phys = <0x5f>;
		phy-names = "usb";
		status = "okay";
	};

	usb@30100000 {
		compatible = "generic-ehci";
		reg = <0x30100000 0x20000>;
		interrupts = <0x0 0x42 0x4>;
		clocks = <0x2 0x1d9 0x5e>;
		phys = <0x60>;
		phy-names = "usb";
		clock-names = "usbhost", "utmi";
		status = "okay";
	};

	usb@30120000 {
		compatible = "generic-ohci";
		reg = <0x30120000 0x20000>;
		interrupts = <0x0 0x43 0x4>;
		clocks = <0x2 0x1d9 0x5e>;
		clock-names = "usbhost", "utmi";
		phys = <0x60>;
		phy-names = "usb";
		status = "okay";
	};

	ethernet@30200000 {
		compatible = "rockchip,rk3228-gmac";
		reg = <0x30200000 0x10000>;
		interrupts = <0x0 0x18 0x4>;
		interrupt-names = "macirq";
		clocks = <0x2 0x7e 0x2 0x81 0x2 0x82 0x2 0x80 0x2 0x7f 0x2 0xd4 0x2 0x16f 0x2 0x83>;
		clock-names = "stmmaceth", "mac_clk_rx", "mac_clk_tx", "clk_mac_ref", "clk_mac_refout", "aclk_mac", "pclk_mac", "clk_macphy";
		resets = <0x2 0x38 0x2 0x3f>;
		reset-names = "stmmaceth", "mac-phy";
		rockchip,grf = <0x38>;
		status = "okay";
		assigned-clocks = <0x2 0x7c>;
		assigned-clock-rates = <0x2faf080>;
		clock_in_out = "output";
		phy-supply = <0x61>;
		phy-mode = "rmii";
		phy-is-integrated;
	};

	qos@31040000 {
		compatible = "syscon";
		reg = <0x31040000 0x20>;
		phandle = <0x21>;
	};

	qos@31070000 {
		compatible = "syscon";
		reg = <0x31070000 0x20>;
		phandle = <0x22>;
	};

	qos@31070080 {
		compatible = "syscon";
		reg = <0x31070080 0x20>;
		phandle = <0x23>;
	};

	interrupt-controller@32010000 {
		compatible = "arm,gic-400";
		interrupt-controller;
		#interrupt-cells = <0x3>;
		#address-cells = <0x0>;
		reg = <0x32011000 0x1000 0x32012000 0x2000 0x32014000 0x2000 0x32016000 0x2000>;
		interrupts = <0x1 0x9 0xf04>;
		phandle = <0x1>;
	};

	pinctrl {
		compatible = "rockchip,rk3228-pinctrl";
		rockchip,grf = <0x38>;
		#address-cells = <0x1>;
		#size-cells = <0x1>;
		ranges;

		gpio0@11110000 {
			compatible = "rockchip,gpio-bank";
			reg = <0x11110000 0x100>;
			interrupts = <0x0 0x33 0x4>;
			clocks = <0x2 0x140>;
			gpio-controller;
			#gpio-cells = <0x2>;
			interrupt-controller;
			#interrupt-cells = <0x2>;
			phandle = <0x77>;
		};

		gpio1@11120000 {
			compatible = "rockchip,gpio-bank";
			reg = <0x11120000 0x100>;
			interrupts = <0x0 0x34 0x4>;
			clocks = <0x2 0x141>;
			gpio-controller;
			#gpio-cells = <0x2>;
			interrupt-controller;
			#interrupt-cells = <0x2>;
			phandle = <0x3e>;
		};

		gpio2@11130000 {
			compatible = "rockchip,gpio-bank";
			reg = <0x11130000 0x100>;
			interrupts = <0x0 0x35 0x4>;
			clocks = <0x2 0x142>;
			gpio-controller;
			#gpio-cells = <0x2>;
			interrupt-controller;
			#interrupt-cells = <0x2>;
			phandle = <0x6d>;
		};

		gpio3@11140000 {
			compatible = "rockchip,gpio-bank";
			reg = <0x11140000 0x100>;
			interrupts = <0x0 0x36 0x4>;
			clocks = <0x2 0x143>;
			gpio-controller;
			#gpio-cells = <0x2>;
			interrupt-controller;
			#interrupt-cells = <0x2>;
			phandle = <0x67>;
		};

		pcfg-pull-up {
			bias-pull-up;
			phandle = <0x65>;
		};

		pcfg-pull-down {
			bias-pull-down;
			phandle = <0x64>;
		};

		pcfg-pull-none {
			bias-disable;
			phandle = <0x63>;
		};

		pcfg-pull-none-drv-12ma {
			drive-strength = <0xc>;
			phandle = <0x62>;
		};

		sdmmc {

			sdmmc-clk {
				rockchip,pins = <0x1 0x10 0x1 0x62>;
				phandle = <0x54>;
			};

			sdmmc-cmd {
				rockchip,pins = <0x1 0xf 0x1 0x62>;
				phandle = <0x55>;
			};

			sdmmc-bus4 {
				rockchip,pins = <0x1 0x12 0x1 0x62 0x1 0x13 0x1 0x62 0x1 0x14 0x1 0x62 0x1 0x15 0x1 0x62>;
				phandle = <0x56>;
			};

			sdmmc-pwr {
				rockchip,pins = <0x1 0xe 0x0 0x63>;
				phandle = <0x53>;
			};
		};

		sdio {

			sdio-clk {
				rockchip,pins = <0x3 0x0 0x1 0x62>;
				phandle = <0x57>;
			};

			sdio-cmd {
				rockchip,pins = <0x3 0x1 0x1 0x62>;
				phandle = <0x58>;
			};

			sdio-bus4 {
				rockchip,pins = <0x3 0x2 0x1 0x62 0x3 0x3 0x1 0x62 0x3 0x4 0x1 0x62 0x3 0x5 0x1 0x62>;
				phandle = <0x59>;
			};
		};

		emmc {

			emmc-clk {
				rockchip,pins = <0x2 0x7 0x2 0x63>;
			};

			emmc-cmd {
				rockchip,pins = <0x1 0x16 0x2 0x63>;
			};

			emmc-bus8 {
				rockchip,pins = <0x1 0x18 0x2 0x63 0x1 0x19 0x2 0x63 0x1 0x1a 0x2 0x63 0x1 0x1b 0x2 0x63 0x1 0x1c 0x2 0x63 0x1 0x1d 0x2 0x63 0x1 0x1e 0x2 0x63 0x1 0x1f 0x2 0x63>;
			};
		};

		gmac {

			rgmii-pins {
				rockchip,pins = <0x2 0xe 0x1 0x63 0x2 0xc 0x1 0x63 0x2 0x19 0x1 0x63 0x2 0x13 0x1 0x62 0x2 0x12 0x1 0x62 0x2 0x16 0x1 0x62 0x2 0x17 0x1 0x62 0x2 0x9 0x1 0x62 0x2 0xd 0x1 0x62 0x2 0x11 0x1 0x63 0x2 0x10 0x1 0x63 0x2 0x15 0x2 0x63 0x2 0x14 0x2 0x63 0x2 0xb 0x1 0x63 0x2 0x8 0x1 0x63>;
			};

			rmii-pins {
				rockchip,pins = <0x2 0xe 0x1 0x63 0x2 0xc 0x1 0x63 0x2 0x19 0x1 0x63 0x2 0x13 0x1 0x62 0x2 0x12 0x1 0x62 0x2 0xd 0x1 0x62 0x2 0x11 0x1 0x63 0x2 0x10 0x1 0x63 0x2 0x8 0x1 0x63 0x2 0xf 0x1 0x63>;
			};

			phy-pins {
				rockchip,pins = <0x2 0xe 0x2 0x63 0x2 0x8 0x2 0x63>;
			};
		};

		hdmi {

			hdmi-hpd {
				rockchip,pins = <0x0 0xf 0x1 0x64>;
				phandle = <0x4f>;
			};

			hdmii2c-xfer {
				rockchip,pins = <0x0 0x6 0x2 0x63 0x0 0x7 0x2 0x63>;
				phandle = <0x4e>;
			};

			hdmi-cec {
				rockchip,pins = <0x0 0x14 0x1 0x63>;
				phandle = <0x50>;
			};
		};

		i2c0 {

			i2c0-xfer {
				rockchip,pins = <0x0 0x0 0x1 0x63 0x0 0x1 0x1 0x63>;
				phandle = <0x2a>;
			};
		};

		i2c1 {

			i2c1-xfer {
				rockchip,pins = <0x0 0x2 0x1 0x63 0x0 0x3 0x1 0x63>;
				phandle = <0x2b>;
			};
		};

		i2c2 {

			i2c2-xfer {
				rockchip,pins = <0x2 0x14 0x1 0x63 0x2 0x15 0x1 0x63>;
				phandle = <0x2c>;
			};
		};

		i2c3 {

			i2c3-xfer {
				rockchip,pins = <0x0 0x6 0x1 0x63 0x0 0x7 0x1 0x63>;
				phandle = <0x2d>;
			};
		};

		tsp {

			tsp-d0 {
				rockchip,pins = <0x2 0x13 0x2 0x63>;
				phandle = <0x11>;
			};

			tsp-d1 {
				rockchip,pins = <0x2 0x12 0x2 0x63>;
				phandle = <0x12>;
			};

			tsp-d2 {
				rockchip,pins = <0x2 0x11 0x2 0x63>;
				phandle = <0x13>;
			};

			tsp-d3 {
				rockchip,pins = <0x2 0x10 0x2 0x63>;
				phandle = <0x14>;
			};

			tsp-d4 {
				rockchip,pins = <0x2 0x19 0x2 0x63>;
				phandle = <0x15>;
			};

			tsp-d5 {
				rockchip,pins = <0x2 0x18 0x2 0x63>;
				phandle = <0x16>;
			};

			tsp-d6 {
				rockchip,pins = <0x2 0xf 0x2 0x63>;
				phandle = <0x17>;
			};

			tsp-d7 {
				rockchip,pins = <0x2 0xd 0x2 0x63>;
				phandle = <0x18>;
			};

			tsp-sync {
				rockchip,pins = <0x2 0xc 0x2 0x63>;
				phandle = <0x19>;
			};

			tsp-clk {
				rockchip,pins = <0x2 0xb 0x2 0x63>;
				phandle = <0x1a>;
			};

			tsp-fail {
				rockchip,pins = <0x2 0xa 0x2 0x63>;
				phandle = <0x1b>;
			};

			tsp-valid {
				rockchip,pins = <0x2 0x9 0x2 0x63>;
				phandle = <0x1c>;
			};
		};

		spi-0 {

			spi0-clk {
				rockchip,pins = <0x0 0x9 0x2 0x65>;
				phandle = <0x2e>;
			};

			spi0-cs0 {
				rockchip,pins = <0x0 0xe 0x2 0x65>;
				phandle = <0x31>;
			};

			spi0-tx {
				rockchip,pins = <0x0 0xb 0x2 0x65>;
				phandle = <0x2f>;
			};

			spi0-rx {
				rockchip,pins = <0x0 0xd 0x2 0x65>;
				phandle = <0x30>;
			};

			spi0-cs1 {
				rockchip,pins = <0x1 0xc 0x1 0x65>;
				phandle = <0x32>;
			};
		};

		spi-1 {

			spi1-clk {
				rockchip,pins = <0x0 0x17 0x2 0x65>;
			};

			spi1-cs0 {
				rockchip,pins = <0x2 0x2 0x2 0x65>;
			};

			spi1-rx {
				rockchip,pins = <0x2 0x0 0x2 0x65>;
			};

			spi1-tx {
				rockchip,pins = <0x2 0x1 0x2 0x65>;
			};

			spi1-cs1 {
				rockchip,pins = <0x2 0x3 0x2 0x65>;
			};
		};

		i2s1 {

			i2s1-bus {
				rockchip,pins = <0x0 0x8 0x1 0x63 0x0 0x9 0x1 0x63 0x0 0xb 0x1 0x63 0x0 0xc 0x1 0x63 0x0 0xd 0x1 0x63 0x0 0xe 0x1 0x63 0x1 0x2 0x2 0x63 0x1 0x4 0x2 0x63 0x1 0x5 0x2 0x63>;
				phandle = <0xf>;
			};
		};

		pwm0 {

			pwm0-pin {
				rockchip,pins = <0x3 0x15 0x1 0x63>;
				phandle = <0x33>;
			};

			pwm0-pin-pull-down {
				rockchip,pins = <0x3 0x15 0x1 0x64>;
			};
		};

		pwm1 {

			pwm1-pin {
				rockchip,pins = <0x0 0x1e 0x2 0x63>;
				phandle = <0x34>;
			};

			pwm1-pin-pull-down {
				rockchip,pins = <0x0 0x1e 0x2 0x64>;
			};
		};

		pwm2 {

			pwm2-pin {
				rockchip,pins = <0x1 0xc 0x2 0x63>;
				phandle = <0x35>;
			};

			pwm2-pin-pull-down {
				rockchip,pins = <0x1 0xc 0x2 0x64>;
			};
		};

		pwm3 {

			pwm3-pin {
				rockchip,pins = <0x1 0xb 0x2 0x63>;
				phandle = <0x36>;
			};

			pwm3-pin-pull-down {
				rockchip,pins = <0x1 0xb 0x2 0x64>;
			};
		};

		spdif {

			spdif-tx {
				rockchip,pins = <0x3 0x1f 0x2 0x63>;
				phandle = <0x10>;
			};
		};

		tsadc {

			otp-gpio {
				rockchip,pins = <0x0 0x18 0x0 0x63>;
				phandle = <0x3c>;
			};

			otp-out {
				rockchip,pins = <0x0 0x18 0x2 0x63>;
				phandle = <0x3d>;
			};
		};

		uart0 {

			uart0-xfer {
				rockchip,pins = <0x2 0x1a 0x1 0x63 0x2 0x1b 0x1 0x63>;
				phandle = <0x24>;
			};

			uart0-cts {
				rockchip,pins = <0x2 0x1d 0x1 0x63>;
				phandle = <0x25>;
			};

			uart0-rts {
				rockchip,pins = <0x0 0x11 0x1 0x63>;
				phandle = <0x26>;
			};
		};

		uart1 {

			uart1-xfer {
				rockchip,pins = <0x1 0x9 0x1 0x63 0x1 0xa 0x1 0x63>;
			};

			uart1-cts {
				rockchip,pins = <0x1 0x8 0x1 0x63>;
			};

			uart1-rts {
				rockchip,pins = <0x1 0xb 0x1 0x63>;
			};
		};

		uart1-1 {

			uart11-xfer {
				rockchip,pins = <0x3 0xe 0x1 0x65 0x3 0xd 0x1 0x63>;
				phandle = <0x27>;
			};

			uart11-cts {
				rockchip,pins = <0x3 0x7 0x1 0x63>;
				phandle = <0x28>;
			};

			uart11-rts {
				rockchip,pins = <0x3 0x6 0x1 0x63>;
				phandle = <0x75>;
			};

			uart11-rts-gpio {
				rockchip,pins = <0x3 0x6 0x0 0x63>;
				phandle = <0x76>;
			};
		};

		uart2 {

			uart2-xfer {
				rockchip,pins = <0x1 0x12 0x2 0x65 0x1 0x13 0x2 0x63>;
			};

			uart2-cts {
				rockchip,pins = <0x0 0x19 0x1 0x63>;
			};

			uart2-rts {
				rockchip,pins = <0x0 0x18 0x1 0x63>;
			};
		};

		uart2-1 {

			uart21-xfer {
				rockchip,pins = <0x1 0xa 0x2 0x65 0x1 0x9 0x2 0x63>;
				phandle = <0x29>;
			};
		};

		keys {

			pwr-key {
				rockchip,pins = <0x3 0x17 0x0 0x65>;
			};
		};

		leds {

			led-standby {
				rockchip,pins = <0x1 0x7 0x0 0x65>;
			};

			led-work {
				rockchip,pins = <0x3 0x15 0x0 0x65>;
			};
		};

		sdio-pwrseq {

			wifi-enable-h {
				rockchip,pins = <0x2 0x1a 0x0 0x63>;
				phandle = <0x6c>;
			};
		};

		usb {

			host-vbus-drv {
				rockchip,pins = <0x3 0x14 0x0 0x63>;
				phandle = <0x70>;
			};

			otg-vbus-drv {
				rockchip,pins = <0x3 0x16 0x0 0x63>;
				phandle = <0x71>;
			};
		};
	};

	rockchip-suspend {
		compatible = "rockchip,pm-rk322x";
		status = "okay";
		rockchip,virtual-poweroff = <0x1>;
		rockchip,sleep-mode-config = <0x10042>;
	};

	fiq-debugger {
		compatible = "rockchip,fiq-debugger";
		interrupts = <0x0 0x51 0x4>;
		rockchip,serial-id = <0x2>;
		rockchip,signal-irq = <0x9f>;
		rockchip,wake-irq = <0x0>;
		rockchip,irq-mode-enable = <0x0>;
		rockchip,baudrate = <0x16e360>;
		pinctrl-names = "default";
		pinctrl-0 = <0x29>;
	};

	firmware {

		android {
			compatible = "android,firmware";

			fstab {
				compatible = "android,fstab";

				system {
					compatible = "android,system";
					dev = "/dev/block/by-name/system";
					type = "ext4";
					mnt_flags = "ro,barrier=1,inode_readahead_blks=8";
					fsmgr_flags = "wait";
				};

				vendor {
					compatible = "android,vendor";
					dev = "/dev/block/by-name/vendor";
					type = "ext4";
					mnt_flags = "ro,barrier=1,inode_readahead_blks=8";
					fsmgr_flags = "wait";
				};
			};
		};
	};

	reserved-memory {
		#address-cells = <0x1>;
		#size-cells = <0x1>;
		ranges;

		drm-logo@00000000 {
			compatible = "rockchip,drm-logo";
			reg = <0x0 0x0>;
			phandle = <0x4a>;
		};

		secure-memory@80000000 {
			compatible = "rockchip,secure-memory";
			reg = <0x80000000 0x0>;
			phandle = <0x4b>;
		};

		ramoops@62e00000 {
			reg = <0x62e00000 0xf0000>;
			phandle = <0x66>;
		};
	};

	ramoops {
		compatible = "ramoops";
		record-size = <0x0 0x20000>;
		console-size = <0x0 0x80000>;
		ftrace-size = <0x0 0x0>;
		pmsg-size = <0x0 0x50000>;
		memory-region = <0x66>;
	};

	psci {
		compatible = "arm,psci-1.0";
		method = "smc";
	};

	leds {
		compatible = "gpio-leds";

		power-red {
			gpios = <0x3e 0x7 0x0>;
			linux,default-trigger = "none";
			default-state = "on";
		};

		power-green {
			gpios = <0x67 0x15 0x0>;
			linux,default-trigger = "none";
			default-state = "off";
		};
	};

	sound {
		compatible = "simple-audio-card";
		simple-audio-card,format = "i2s";
		simple-audio-card,mclk-fs = <0x100>;
		simple-audio-card,name = "rockchip,rk3229";

		simple-audio-card,cpu {
			sound-dai = <0x68>;
		};

		simple-audio-card,codec {
			sound-dai = <0x69>;
		};
	};

	hdmi-sound {
		status = "okay";
		compatible = "simple-audio-card";
		simple-audio-card,format = "i2s";
		simple-audio-card,mclk-fs = <0x80>;
		simple-audio-card,name = "rockchip,hdmi";

		simple-audio-card,cpu {
			sound-dai = <0x6a>;
		};

		simple-audio-card,codec {
			sound-dai = <0x6b>;
		};
	};

	regulators {
		compatible = "simple-bus";
		#address-cells = <0x1>;
		#size-cells = <0x0>;

		regulator@0 {
			compatible = "regulator-fixed";
			regulator-name = "vccio_1v8";
			regulator-min-microvolt = <0x1b7740>;
			regulator-max-microvolt = <0x1b7740>;
			regulator-always-on;
			phandle = <0x1e>;
		};

		regulator@1 {
			compatible = "regulator-fixed";
			regulator-name = "vccio_3v3";
			regulator-min-microvolt = <0x325aa0>;
			regulator-max-microvolt = <0x325aa0>;
			regulator-always-on;
			phandle = <0x1d>;
		};
	};

	sdio-pwrseq {
		compatible = "mmc-pwrseq-simple";
		pinctrl-names = "default";
		pinctrl-0 = <0x6c>;
		reset-gpios = <0x6d 0x1a 0x1>;
		phandle = <0x5a>;
	};

	spdif-out {
		status = "okay";
		compatible = "linux,spdif-dit";
		#sound-dai-cells = <0x0>;
		phandle = <0x6f>;
	};

	spdif-sound {
		status = "okay";
		compatible = "simple-audio-card";
		simple-audio-card,name = "ROCKCHIP,SPDIF";

		simple-audio-card,cpu {
			sound-dai = <0x6e>;
		};

		simple-audio-card,codec {
			sound-dai = <0x6f>;
		};
	};

	vcc-host-regulator {
		compatible = "regulator-fixed";
		enable-active-high;
		gpio = <0x67 0x14 0x0>;
		pinctrl-names = "default";
		pinctrl-0 = <0x70>;
		regulator-name = "vcc_host";
		regulator-always-on;
		regulator-boot-on;
		phandle = <0x20>;
	};

	otg-vbus-regulator {
		compatible = "regulator-fixed";
		gpio = <0x67 0x16 0x0>;
		pinctrl-names = "default";
		pinctrl-0 = <0x71>;
		regulator-name = "vcc_otg_vbus";
		regulator-min-microvolt = <0x4c4b40>;
		regulator-max-microvolt = <0x4c4b40>;
		enable-active-high;
		phandle = <0x1f>;
	};

	vcc-phy-regulator {
		compatible = "regulator-fixed";
		enable-active-high;
		regulator-name = "vcc_phy";
		regulator-min-microvolt = <0x1b7740>;
		regulator-max-microvolt = <0x1b7740>;
		regulator-always-on;
		regulator-boot-on;
		phandle = <0x61>;
	};

	vdd-arm-regulator {
		compatible = "pwm-regulator";
		rockchip,pwm_id = <0x1>;
		rockchip,pwm_voltage = <0x10c8e0>;
		pwms = <0x72 0x0 0x1388 0x1>;
		regulator-name = "vdd_arm";
		regulator-min-microvolt = <0xe7ef0>;
		regulator-max-microvolt = <0x155cc0>;
		regulator-settling-time-up-us = <0xfa>;
		regulator-always-on;
		regulator-boot-on;
		phandle = <0x4>;
	};

	vdd-log-regulator {
		compatible = "pwm-regulator";
		rockchip,pwm_id = <0x2>;
		rockchip,pwm_voltage = <0x124f80>;
		pwms = <0x73 0x0 0x1388 0x1>;
		regulator-name = "vdd_log";
		regulator-min-microvolt = <0xf4240>;
		regulator-max-microvolt = <0x13d620>;
		regulator-settling-time-up-us = <0xfa>;
		regulator-always-on;
		regulator-boot-on;
		phandle = <0xc>;
	};

	wireless-bluetooth {
		compatible = "bluetooth-platdata";
		clocks = <0x74>;
		clock-names = "ext_clock";
		uart_rts_gpios = <0x67 0x6 0x1>;
		pinctrl-names = "default", "rts_gpio";
		pinctrl-0 = <0x75>;
		pinctrl-1 = <0x76>;
		BT,power_gpio = <0x6d 0x1d 0x0>;
		BT,wake_host_irq = <0x67 0x1a 0x0>;
		status = "disabled";
	};

	wireless-wlan {
		compatible = "wlan-platdata";
		rockchip,grf = <0x38>;
		wifi_chip_type = "rtl8189es";
		sdio_vref = <0xce4>;
		WIFI,host_wake_irq = <0x77 0x1c 0x0>;
		status = "okay";
	};
};
